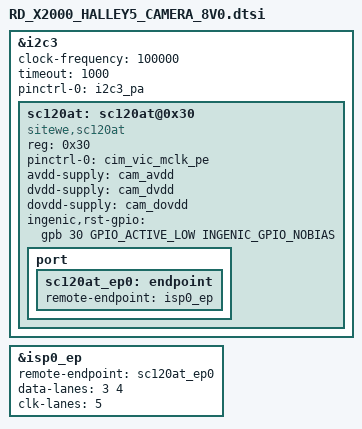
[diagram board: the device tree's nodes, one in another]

&i2c3 {
	status = "okay";
	clock-frequency = <100000>;
	timeout = <1000>;
	pinctrl-names = "default";
	pinctrl-0 = <&i2c3_pa>;

	/*RD_X2000_HALLEY5_CAMERA_V8.0 mipi interface*/
	sc120at:sc120at@0x30 {
		status = "ok";
		compatible = "sitewe,sc120at";
		reg = <0x30>;
		pinctrl-names = "default";
		pinctrl-0 = <&cim_vic_mclk_pe>;

		avdd-supply = <&cam_avdd>;
		dvdd-supply = <&cam_dvdd>;
		dovdd-supply = <&cam_dovdd>;
		ingenic,rst-gpio = <&gpb 30 GPIO_ACTIVE_LOW INGENIC_GPIO_NOBIAS>;

		port {
			sc120at_ep0:endpoint {
				remote-endpoint = <&isp0_ep>;
			};
		};
	};


};



&isp0_ep {
	remote-endpoint = <&sc120at_ep0>;
	data-lanes = <3 4>;
	clk-lanes = <5>;
};
